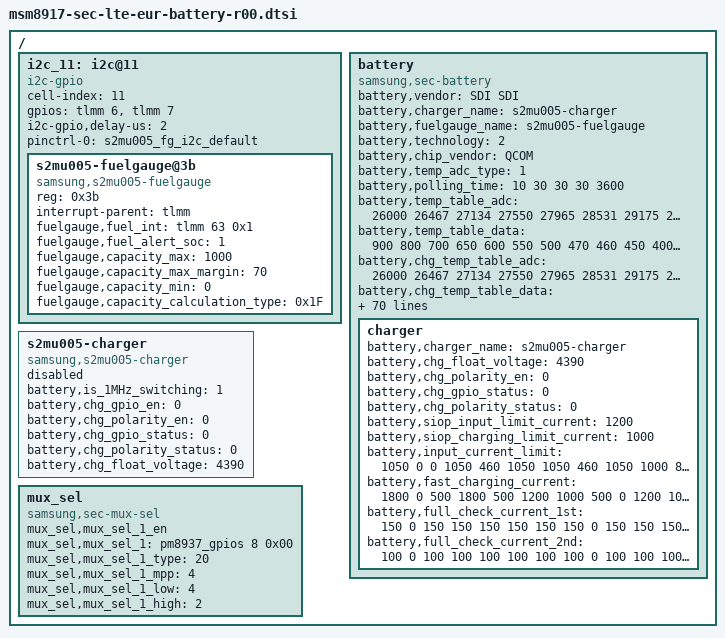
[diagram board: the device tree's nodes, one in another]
/* Copyright (c) 2015, The Linux Foundation. All rights reserved.
 *
 * This program is free software; you can redistribute it and/or modify
 * it under the terms of the GNU General Public License version 2 and
 * only version 2 as published by the Free Software Foundation.
 *
 * This program is distributed in the hope that it will be useful,
 * but WITHOUT ANY WARRANTY; without even the implied warranty of
 * MERCHANTABILITY or FITNESS FOR A PARTICULAR PURPOSE.  See the
 * GNU General Public License for more details.
 */

/ {
	i2c_11: i2c@11 {
		cell-index = <11>;
		compatible = "i2c-gpio";
		gpios = <&tlmm 6 0 /* sda */
			&tlmm 7 0 /* scl */
			>;
		i2c-gpio,delay-us = <2>;
		pinctrl-names = "s2mu005_fg_i2c_pin_default";
		pinctrl-0 = <&s2mu005_fg_i2c_default>;
		#address-cells = <1>;
		#size-cells = <0>;

		s2mu005-fuelgauge@3b{
			compatible = "samsung,s2mu005-fuelgauge";
			reg = <0x3b>;
			interrupt-parent = <&tlmm>;
			fuelgauge,fuel_int = <&tlmm 63 0x1>;
			fuelgauge,fuel_alert_soc = <1>;
			fuelgauge,capacity_max = <1000>;
			fuelgauge,capacity_max_margin = <70>;
			fuelgauge,capacity_min = <0>;
			fuelgauge,capacity_calculation_type = <0x1F>;
		};
	};

	battery {
		status = "okay";
		compatible = "samsung,sec-battery";
		battery,vendor = "SDI SDI";
		battery,charger_name = "s2mu005-charger";
		battery,fuelgauge_name = "s2mu005-fuelgauge";
		battery,technology = <2>; /* POWER_SUPPLY_TECHNOLOGY_LION */

		battery,chip_vendor = "QCOM";
		battery,temp_adc_type = <1>; /* SEC_BATTERY_ADC_TYPE_AP */

		battery,polling_time = <10 30 30 30 3600>;

		battery,temp_table_adc = <26000 26467 27134 27550 27965 28531 29175 29600 29760 29919 30792 32737 34869 37004 38534 38861 39764 40457 41041 41518>;

		battery,temp_table_data = <900 800 700 650 600 550 500 470 460 450 400 300 200 100 20 0 (-50) (-100) (-150) (-200)>;

		battery,chg_temp_table_adc = <26000 26467 27134 27550 27965 28531 29175 29600 29760 29919 30792 32737 34869 37004 38534 38861 39764 40457 41041 41518>;

		battery,chg_temp_table_data = <900 800 700 650 600 550 500 470 460 450 400 300 200 100 20 0 (-50) (-100) (-150) (-200)>;
		battery,adc_check_count = <5>;

		battery,cable_check_type = <4>; /* SEC_BATTERY_CABLE_CHECK_PSY */
		battery,cable_source_type = <3>; /* SEC_BATTERY_CABLE_SOURCE_EXTERNAL */
		battery,event_waiting_time = <600>;
		battery,polling_type = <1>; /* SEC_BATTERY_MONITOR_ALARM */
		battery,monitor_initial_count = <3>;

		battery,battery_check_type = <0>; /* SEC_BATTERY_CHECK_CHARGER */
		battery,check_count = <0>;
		battery,check_adc_max = <1440>;
		battery,check_adc_min = <0>;

		battery,ovp_uvlo_check_type = <3>; /* SEC_BATTERY_OVP_UVLO_CHGPOLLING */

		battery,thermal_source = <2>; /* SEC_BATTERY_THERMAL_SOURCE_ADC */

		battery,temp_check_type = <2>; /* SEC_BATTERY_TEMP_CHECK_TEMP */
		battery,temp_check_count = <1>;
		battery,temp_highlimit_threshold_event = <800>;
		battery,temp_highlimit_recovery_event = <750>;
		battery,temp_high_threshold_event = <550>;
		battery,temp_high_recovery_event = <500>;
		battery,temp_low_threshold_event = <(-50)>;
		battery,temp_low_recovery_event = <0>;
		battery,temp_highlimit_threshold_normal = <800>;
		battery,temp_highlimit_recovery_normal = <750>;
		battery,temp_high_threshold_normal = <550>;
		battery,temp_high_recovery_normal = <500>;
		battery,temp_low_threshold_normal = <(-50)>;
		battery,temp_low_recovery_normal = <0>;
		battery,temp_highlimit_threshold_lpm = <800>;
		battery,temp_highlimit_recovery_lpm = <750>;
		battery,temp_high_threshold_lpm = <550>;
		battery,temp_high_recovery_lpm = <500>;
		battery,temp_low_threshold_lpm = <(-50)>;
		battery,temp_low_recovery_lpm = <0>;
		battery,full_check_type = <2>; /* SEC_BATTERY_FULLCHARGED_FG_CURRENT */
		battery,full_check_type_2nd = <2>; /* SEC_BATTERY_FULLCHARGED_FG_CURRENT */
		battery,full_check_count = <1>;
		battery,chg_gpio_full_check = <0>;
		battery,chg_polarity_full_check = <1>;

		/* SEC_BATTERY_FULL_CONDITION_SOC |
		   SEC_BATTERY_FULL_CONDITION_NOTIMEFULL |
		   SEC_BATTERY_FULL_CONDITION_VCELL */
		battery,full_condition_type = <13>;
		battery,full_condition_soc = <93>;
		battery,full_condition_vcell = <4300>;

		battery,recharge_check_count = <1>;
		battery,recharge_condition_type = <4>; /* SEC_BATTERY_RECHARGE_CONDITION_VCELL */
		battery,recharge_condition_soc = <98>;
		battery,recharge_condition_vcell = <4330>;

		//battery,self_discharging_en;
		battery,self_discharging_type = <2>;	/* SEC_BAT_SELF_DISCHARGING_BY_CHG */
		//battery,factory_discharging = <&expander_gpios 13 0x00>;

		battery,force_discharging_limit = <600>;
		battery,force_discharging_recov = <550>;
		battery,self_discharging_voltage_limit = <4250>;
		battery,discharging_adc_max = <29864>;
		battery,discharging_adc_min = <25768>;
		battery,discharging_ntc_limit = <2750>;

		battery,charging_total_time = <21600>;
		battery,recharging_total_time = <5400>;
		battery,charging_reset_time = <0>;

		battery,swelling_high_temp_block = <500>;
		battery,swelling_high_temp_recov = <450>;
		battery,swelling_low_temp_block = <50>;
		battery,swelling_low_temp_recov = <100>;
		battery,swelling_chg_current = <1500>;
		battery,swelling_drop_float_voltage = <4200>;
		battery,swelling_high_rechg_voltage = <4150>;
		battery,swelling_low_rechg_voltage = <4050>;
		battery,swelling_block_time = <600>;

		battery,self_discharging_temp_block = <600>;
		battery,self_discharging_volt_block = <4250>;
		battery,self_discharging_temp_recov = <550>;
		battery,self_discharging_temp_pollingtime = <400>;

		battery,chg_eoc_dualpath;

		qcom,sec-battery-vadc = <&pm8937_vadc>;

		charger {
			battery,charger_name = "s2mu005-charger";
			battery,chg_float_voltage = <4390>;

			battery,chg_polarity_en = <0>;
			battery,chg_gpio_status = <0>;
			battery,chg_polarity_status = <0>;

			battery,siop_input_limit_current = <1200>;
			battery,siop_charging_limit_current = <1000>;

			battery,input_current_limit = <1050 0 0 1050 460 1050 1050 460 1050 1000 820 1050 1050 0 1050 300 700 1050 1050 300 80 900 1050 1000 1000 1600 1600 1600 1400 900 820 820 900 1000 1000>;
			battery,fast_charging_current = <1800 0 500 1800 500 1200 1000 500 0 1200 1000 1800 1800 0 1300 300 700 1300 1500 300 80 1200 1500 1000 1000 3150 1000 3000 1400 1200 1000 1000 1200 0 1000>;
			battery,full_check_current_1st = <150 0 150 150 150 150 150 150 0 150 150 150 150 0 150 150 150 150 150 150 150 150 0 150 150 150 150 150 150 150 150 150 150 0 150>;
			battery,full_check_current_2nd = <100 0 100 100 100 100 100 100 0 100 100 100 100 0 100 100 100 100 100 100 100 100 0 100 100 100 100 100 100 100 100 100 100 0 100>;
		};
	};

	s2mu005-charger {
		status = "disable";
		compatible = "samsung,s2mu005-charger";
		battery,is_1MHz_switching = <1>;
		battery,chg_gpio_en = <0>;
		battery,chg_polarity_en = <0>;
		battery,chg_gpio_status = <0>;
		battery,chg_polarity_status = <0>;
		battery,chg_float_voltage = <4390>;
	};

	mux_sel {
		compatible = "samsung,sec-mux-sel";
		mux_sel,mux_sel_1_en;
		mux_sel,mux_sel_1 = <&pm8937_gpios 8 0x00>;
		mux_sel,mux_sel_1_type = <20>; /* BATT_THM_MUX_SEL | AP_THM_MUX_SEL */
		mux_sel,mux_sel_1_mpp = <4>; /* SEC_MPP4_MUX_SEL */
		mux_sel,mux_sel_1_low = <4>; /* SEC_MUX_SEL_AP_THM */
		mux_sel,mux_sel_1_high = <2>; /* SEC_MUX_SEL_BATT_THM */
	};
};
